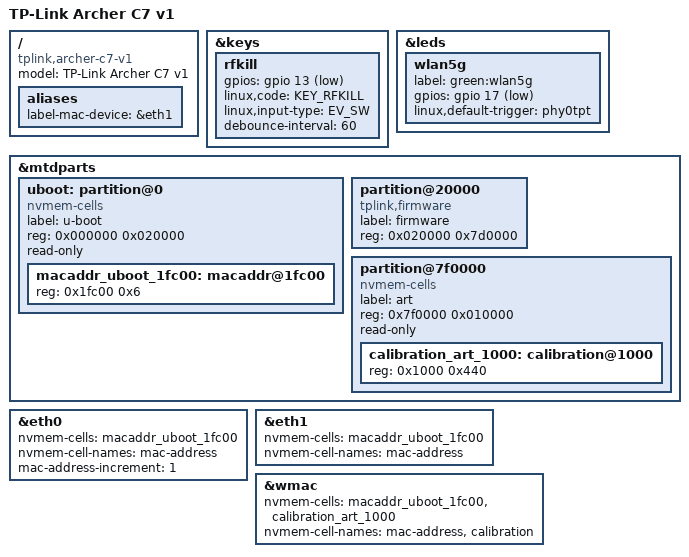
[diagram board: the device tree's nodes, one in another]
// SPDX-License-Identifier: GPL-2.0-or-later OR MIT

#include "qca9558_tplink_archer-c.dtsi"

/ {
	compatible = "tplink,archer-c7-v1", "qca,qca9558";
	model = "TP-Link Archer C7 v1";

	aliases {
		label-mac-device = &eth1;
	};
};

&keys {
	rfkill {
		gpios = <&gpio 13 GPIO_ACTIVE_LOW>;
		linux,code = <KEY_RFKILL>;
		linux,input-type = <EV_SW>;
		debounce-interval = <60>;
	};
};

&leds {
	wlan5g {
		label = "green:wlan5g";
		gpios = <&gpio 17 GPIO_ACTIVE_LOW>;
		linux,default-trigger = "phy0tpt";
	};
};

&mtdparts {
	uboot: partition@0 {
		label = "u-boot";
		reg = <0x000000 0x020000>;
		read-only;
	};

	partition@20000 {
		label = "firmware";
		compatible = "tplink,firmware";
		reg = <0x020000 0x7d0000>;
	};

	partition@7f0000 {
		label = "art";
		reg = <0x7f0000 0x010000>;
		read-only;

		compatible = "nvmem-cells";
		#address-cells = <1>;
		#size-cells = <1>;

		calibration_art_1000: calibration@1000 {
			reg = <0x1000 0x440>;
		};
	};
};

&eth0 {
	nvmem-cells = <&macaddr_uboot_1fc00>;
	nvmem-cell-names = "mac-address";
	mac-address-increment = <1>;
};

&eth1 {
	nvmem-cells = <&macaddr_uboot_1fc00>;
	nvmem-cell-names = "mac-address";
};

&wmac {
	nvmem-cells = <&macaddr_uboot_1fc00>, <&calibration_art_1000>;
	nvmem-cell-names = "mac-address", "calibration";
};

&uboot {
	compatible = "nvmem-cells";
	#address-cells = <1>;
	#size-cells = <1>;

	macaddr_uboot_1fc00: macaddr@1fc00 {
		reg = <0x1fc00 0x6>;
	};
};
